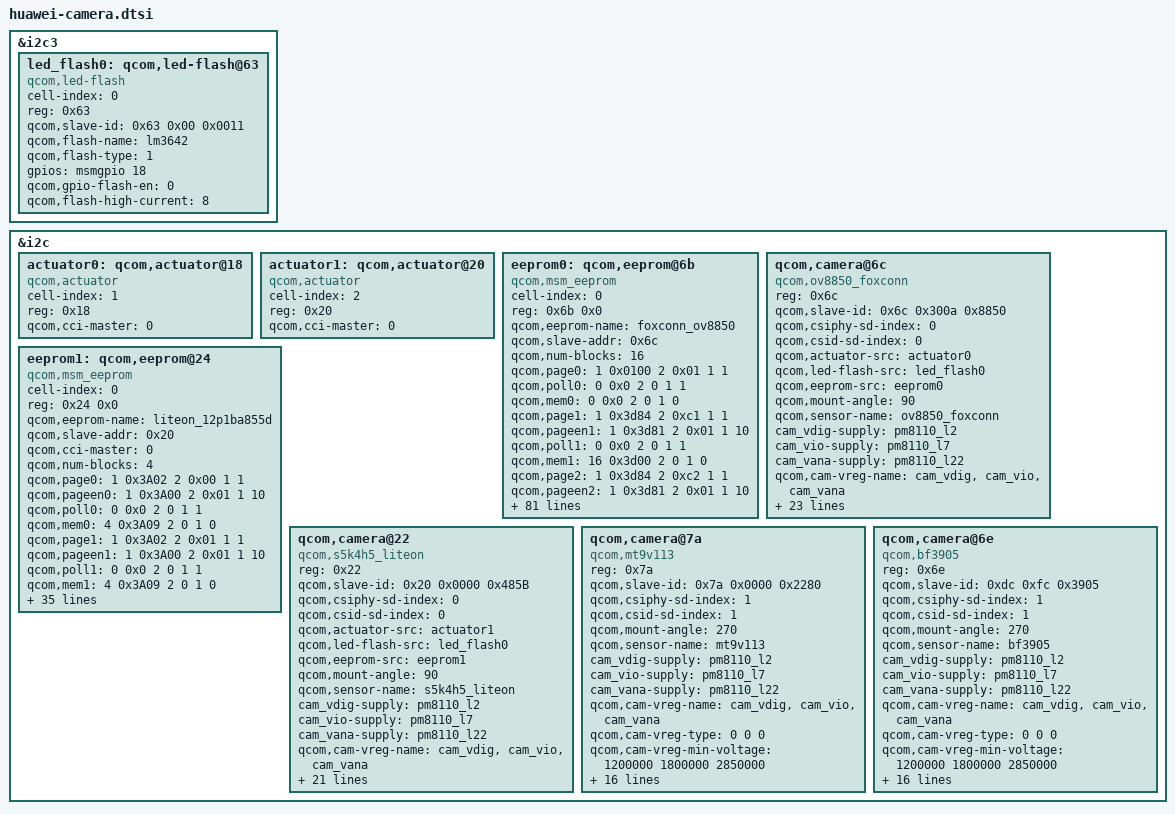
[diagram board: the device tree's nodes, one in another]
/*
 * Copyright (c) 2012-2013, The Linux Foundation. All rights reserved.
 *
 * This program is free software; you can redistribute it and/or modify
 * it under the terms of the GNU General Public License version 2 and
 * only version 2 as published by the Free Software Foundation.
 *
 * This program is distributed in the hope that it will be useful,
 * but WITHOUT ANY WARRANTY; without even the implied warranty of
 * MERCHANTABILITY or FITNESS FOR A PARTICULAR PURPOSE.  See the
 * GNU General Public License for more details.
 */
&i2c3 {
       led_flash0: qcom,led-flash@63 {
		cell-index = <0>;
		reg = <0x63>;
		qcom,slave-id = <0x63 0x00 0x0011>;
		compatible = "qcom,led-flash";
		qcom,flash-name = "lm3642";
		qcom,flash-type = <1>;
		gpios = <&msmgpio 18 0>;
		qcom,gpio-flash-en = <0>;
		// 8 corresponds to 656.25mA
		qcom,flash-high-current = <8>;
       };
};

&i2c {

		actuator0: qcom,actuator@18 {
			cell-index = <1>;
			reg = <0x18>;
			compatible = "qcom,actuator";
			qcom,cci-master = <0>;
		};
		actuator1: qcom,actuator@20 {
			cell-index = <2>;
			reg = <0x20>;
			compatible = "qcom,actuator";
			qcom,cci-master = <0>;
		};
		eeprom0: qcom,eeprom@6b {
		cell-index = <0>;
		reg = <0x6b 0x0>;
		qcom,eeprom-name = "foxconn_ov8850";
		compatible = "qcom,msm_eeprom";
		qcom,slave-addr = <0x6c>;
		qcom,num-blocks = <16>;

		qcom,page0 = <1 0x0100 2 0x01 1 1>;
		qcom,poll0 = <0 0x0 2 0 1 1>;
		qcom,mem0 = <0 0x0 2 0 1 0>;
		qcom,page1 = <1 0x3d84 2 0xc1 1 1>;
		qcom,pageen1 = <1 0x3d81 2 0x01 1 10>;
		qcom,poll1 = <0 0x0 2 0 1 1>;
		qcom,mem1 = <16 0x3d00 2 0 1 0>;
		qcom,page2 = <1 0x3d84 2 0xc2 1 1>;
		qcom,pageen2 = <1 0x3d81 2 0x01 1 10>;
		qcom,poll2 = <0 0x0 2 0 1 1>;
		qcom,mem2 = <16 0x3d00 2 0 1 0>;
		qcom,page3 = <1 0x3d84 2 0xc3 1 1>;
		qcom,pageen3 = <1 0x3d81 2 0x01 1 10>;
		qcom,poll3 = <0 0x0 2 0 1 1>;
		qcom,mem3 = <16 0x3d00 2 0 1 0>;
		qcom,page4 = <1 0x3d84 2 0xc4 1 1>;
		qcom,pageen4 = <1 0x3d81 2 0x01 1 10>;
		qcom,poll4 = <0 0x0 2 0 1 1>;
		qcom,mem4 = <16 0x3d00 2 0 1 0>;
		qcom,page5 = <1 0x3d84 2 0xc5 1 1>;
		qcom,pageen5 = <1 0x3d81 2 0x01 1 10>;
		qcom,poll5 = <0 0x0 2 0 1 1>;
		qcom,mem5 = <16 0x3d00 2 0 1 0>;
		qcom,page6 = <1 0x3d84 2 0xc6 1 1>;
		qcom,pageen6 = <1 0x3d81 2 0x01 1 10>;
		qcom,poll6 = <0 0x0 2 0 1 1>;
		qcom,mem6 = <16 0x3d00 2 0 1 0>;
		qcom,page7 = <1 0x3d84 2 0xc7 1 1>;
		qcom,pageen7 = <1 0x3d81 2 0x01 1 10>;
		qcom,poll7 = <0 0x0 2 0 1 1>;
		qcom,mem7 = <16 0x3d00 2 0 1 0>;
		qcom,page8 = <1 0x3d84 2 0xc8 1 1>;
		qcom,pageen8 = <1 0x3d81 2 0x01 1 10>;
		qcom,poll8 = <0 0x0 2 0 1 1>;
		qcom,mem8 = <16 0x3d00 2 0 1 0>;
		qcom,page9 = <1 0x3d84 2 0xc9 1 1>;
		qcom,pageen9 = <1 0x3d81 2 0x01 1 10>;
		qcom,poll9 = <0 0x0 2 0 1 1>;
		qcom,mem9 = <16 0x3d00 2 0 1 0>;
		qcom,page10 = <1 0x3d84 2 0xca 1 1>;
		qcom,pageen10 = <1 0x3d81 2 0x01 1 10>;
		qcom,poll10 = <0 0x0 2 0 1 1>;
		qcom,mem10 = <16 0x3d00 2 0 1 0>;
		qcom,page11 = <1 0x3d84 2 0xcb 1 1>;
		qcom,pageen11 = <1 0x3d81 2 0x01 1 10>;
		qcom,poll11 = <0 0x0 2 0 1 1>;
		qcom,mem11 = <16 0x3d00 2 0 1 0>;
		qcom,page12 = <1 0x3d84 2 0xcc 1 1>;
		qcom,pageen12 = <1 0x3d81 2 0x01 1 10>;
		qcom,poll12 = <0 0x0 2 0 1 1>;
		qcom,mem12 = <16 0x3d00 2 0 1 0>;
		qcom,page13 = <1 0x3d84 2 0xcd 1 1>;
		qcom,pageen13 = <1 0x3d81 2 0x01 1 10>;
		qcom,poll13 = <0 0x0 2 0 1 1>;
		qcom,mem13 = <16 0x3d00 2 0 1 0>;
		qcom,page14 = <1 0x3d84 2 0xce 1 1>;
		qcom,pageen14 = <1 0x3d81 2 0x01 1 10>;
		qcom,poll14 = <0 0x0 2 0 1 1>;
		qcom,mem14 = <16 0x3d00 2 0 1 0>;
		qcom,page15 = <1 0x3d84 2 0xcf 1 1>;
		qcom,pageen15 = <1 0x3d81 2 0x01 1 10>;
		qcom,poll15 = <0 0x0 2 0 1 1>;
		qcom,mem15 = <16 0x3d00 2 0 1 0>;

		cam_vdig-supply = <&pm8110_l2>;
		cam_vio-supply = <&pm8110_l7>;
		cam_vana-supply = <&pm8110_l22>;
		qcom,cam-vreg-name = "cam_vdig", "cam_vio", "cam_vana";
		qcom,cam-vreg-type = <0 0 0>;
		qcom,cam-vreg-min-voltage = <0 1800000 2850000>;
		qcom,cam-vreg-max-voltage = <0 1800000 2850000>;
		qcom,cam-vreg-op-mode = <0 200000 100000>;
		qcom,gpio-no-mux = <0>;
		gpios = <&msmgpio 13 0>,
			<&msmgpio 21 0>,//reset
			<&msmgpio 20 0>,//stanby
			<&msmgpio 101 0>; //dvdd_en
		qcom,gpio-reset = <1>;
		qcom,gpio-standby = <2>;
		qcom,gpio-vdig = <3>;
		qcom,gpio-req-tbl-num = <0 1 2 3>;
		qcom,gpio-req-tbl-flags = <1 0 0 0>;
		qcom,gpio-req-tbl-label = "CAMIF_MCLK",
			"CAM_RESET1",
			"CAM_STANDBY",
			"CAM_DVDD_EN";
		qcom,cam-power-seq-type = "sensor_gpio",
			"sensor_vreg", "sensor_vreg", "sensor_clk",
			"sensor_gpio", "sensor_gpio";
		qcom,cam-power-seq-val = "sensor_gpio_vdig",
			"cam_vio", "cam_vana", "sensor_cam_mclk",
			"sensor_gpio_reset",
			"sensor_gpio_standby";
		qcom,cam-power-seq-cfg-val = <1 1 1 24000000 1 1>;
		qcom,cam-power-seq-delay = <1 1 5 5 5 10>;
	};	
		/* change the mount angle of the ov8850 & s5k4h5 from 270 to 90*/
		qcom,camera@6c {
				compatible = "qcom,ov8850_foxconn";
				reg = <0x6c>;
				qcom,slave-id = <0x6c 0x300a 0x8850>;
				qcom,csiphy-sd-index = <0>;
				qcom,csid-sd-index = <0>;
				qcom,actuator-src = <&actuator0>;
				qcom,led-flash-src = <&led_flash0>;
				qcom,eeprom-src = <&eeprom0>;
				qcom,mount-angle = <90>;
				qcom,sensor-name = "ov8850_foxconn";
				cam_vdig-supply = <&pm8110_l2>;
				cam_vio-supply = <&pm8110_l7>;
				cam_vana-supply = <&pm8110_l22>;
				qcom,cam-vreg-name = "cam_vdig", "cam_vio", "cam_vana";
				qcom,cam-vreg-type = <0 0 0>;
				qcom,cam-vreg-min-voltage = <1200000 1800000 2850000>;
				qcom,cam-vreg-max-voltage = <1200000 1800000 2850000>;
				qcom,cam-vreg-op-mode = <200000 200000 100000>;
				qcom,gpio-no-mux = <0>;
				gpios = <&msmgpio 13 0>,
					<&msmgpio 21 0>,//reset
					<&msmgpio 20 0>,//stanby
					<&msmgpio 101 0>, //dvdd_en
					<&msmgpio 79 0>; //vcm_pwdn
				qcom,gpio-reset = <1>;
				qcom,gpio-standby = <2>;
				qcom,gpio-vdig = <3>;
				qcom,gpio-af-pwdm = <4>;
				qcom,gpio-req-tbl-num = <0 1 2 3 4>;
				qcom,gpio-req-tbl-flags = <1 0 0 0 0>;
				qcom,gpio-req-tbl-label = "CAMIF_MCLK",
					"CAM_RESET1",
					"CAM_STANDBY",
					"CAM_DVDDEN",
					"CAM_VCMPWDN";
				qcom,csi-lane-assign = <0xe4>;
				qcom,csi-lane-mask = <0x7>;
				qcom,sensor-position = <0>;
				qcom,sensor-mode = <1>;
				qcom,cci-master = <0>;
			};
		eeprom1: qcom,eeprom@24 {		
				cell-index = <0>;		
				reg = <0x24 0x0>;		
				qcom,eeprom-name = "liteon_12p1ba855d";	
				compatible = "qcom,msm_eeprom";		
				qcom,slave-addr = <0x20>;	
				qcom,cci-master = <0>;
				qcom,num-blocks = <4>;	
				qcom,page0 = <1 0x3A02 2 0x00 1 1>;	
				qcom,pageen0 = <1 0x3A00 2 0x01 1 10>;	
				qcom,poll0 = <0 0x0 2 0 1 1>;	
				qcom,mem0 = <4 0x3A09 2 0 1 0>;	
				qcom,page1 = <1 0x3A02 2 0x01 1 1>;	
				qcom,pageen1 = <1 0x3A00 2 0x01 1 10>;	
				qcom,poll1 = <0 0x0 2 0 1 1>;	
				qcom,mem1 = <4 0x3A09 2 0 1 0>;	
				qcom,page2 = <1 0x3A02 2 0x02 1 1>;	
				qcom,pageen2 = <1 0x3A00 2 0x01 1 10>;	
				qcom,poll2 = <0 0x0 2 0 1 1>;	
				qcom,mem2 = <4 0x3A09 2 0 1 0>;	
				qcom,page3 = <1 0x3A02 2 0x03 1 1>;	
				qcom,pageen3 = <1 0x3A00 2 0x01 1 10>;	
				qcom,poll3 = <0 0x0 2 0 1 1>;	
				qcom,mem3 = <4 0x3A09 2 0 1 0>;	
				
				cam_vdig-supply = <&pm8110_l2>;	
				cam_vio-supply = <&pm8110_l7>;	
				cam_vana-supply = <&pm8110_l22>;
				qcom,cam-vreg-name = "cam_vdig", "cam_vio", "cam_vana";
				qcom,cam-vreg-type = <0 0 0>;
				qcom,cam-vreg-min-voltage = <1200000 1800000 2850000>;
				qcom,cam-vreg-max-voltage = <1200000 1800000 2850000>;
				qcom,cam-vreg-op-mode = <200000 200000 100000>;
				
				qcom,gpio-no-mux = <0>;
				gpios = <&msmgpio 13 0>,		
					<&msmgpio 21 0>,//reset
					<&msmgpio 101 0>; //dvdd_en
				qcom,gpio-reset = <1>;	
				qcom,gpio-vdig  = <2>;
				qcom,gpio-req-tbl-num = <0 1 2>;
				qcom,gpio-req-tbl-flags = <1 0 0>;	
				qcom,gpio-req-tbl-label = "CAMIF_MCLK",	
					"CAM_RESET1",
					"CAM_DVDD_EN";
				qcom,cam-power-seq-type = "sensor_gpio",
					"sensor_vreg", 
					"sensor_vreg",
					"sensor_vreg",
					"sensor_clk",		
					"sensor_gpio";		
				qcom,cam-power-seq-val = "sensor_gpio_vdig",
					"cam_vdig",
					"cam_vana",
					"cam_vio", 
					"sensor_cam_mclk",			
					"sensor_gpio_reset";	
				qcom,cam-power-seq-cfg-val = <1 1 1 1 24000000 1>;	
				qcom,cam-power-seq-delay =   <1 1 1 1 5 5>;
		};
		qcom,camera@22 {
				compatible = "qcom,s5k4h5_liteon";
				reg = <0x22>;
				qcom,slave-id = <0x20 0x0000 0x485B>;
				qcom,csiphy-sd-index = <0>;
				qcom,csid-sd-index = <0>;
				qcom,actuator-src = <&actuator1>;
				qcom,led-flash-src = <&led_flash0>;
				qcom,eeprom-src = <&eeprom1>;
				qcom,mount-angle = <90>;
				qcom,sensor-name = "s5k4h5_liteon";
				cam_vdig-supply = <&pm8110_l2>;
				cam_vio-supply = <&pm8110_l7>;
				cam_vana-supply = <&pm8110_l22>;
				qcom,cam-vreg-name = "cam_vdig", "cam_vio", "cam_vana";
				qcom,cam-vreg-type = <0 0 0>;
				qcom,cam-vreg-min-voltage = <1200000 1800000 2850000>;
				qcom,cam-vreg-max-voltage = <1200000 1800000 2850000>;
				qcom,cam-vreg-op-mode = <200000 200000 100000>;
				qcom,gpio-no-mux = <0>;
				gpios = <&msmgpio 13 0>,
					<&msmgpio 21 0>,//reset
					<&msmgpio 101 0>, //dvdd_en
					<&msmgpio 79 0>; //vcm_pwdn
				qcom,gpio-reset = <1>;
				qcom,gpio-vdig = <2>;
				qcom,gpio-af-pwdm = <3>;
				qcom,gpio-req-tbl-num = <0 1 2 3>;
				qcom,gpio-req-tbl-flags = <1 0 0 0>;
				qcom,gpio-req-tbl-label = "CAMIF_MCLK",
					"CAM_RESET1",
					"CAM_DVDDEN",
					"CAM_VCMPWDN";
				qcom,csi-lane-assign = <0xe4>;
				qcom,csi-lane-mask = <0x3>;
				qcom,sensor-position = <0>;
				qcom,sensor-mode = <1>;
				qcom,cci-master = <0>;
			};
			
  qcom,camera@7a {
		  compatible = "qcom,mt9v113";
		  reg = <0x7a>;
		  qcom,slave-id = <0x7a 0x0000 0x2280>;
		  qcom,csiphy-sd-index = <1>;
		  qcom,csid-sd-index = <1>;
		  qcom,mount-angle = <270>;
		  qcom,sensor-name = "mt9v113";
		  cam_vdig-supply = <&pm8110_l2>;
		  cam_vio-supply = <&pm8110_l7>;
		  cam_vana-supply = <&pm8110_l22>;
		  qcom,cam-vreg-name = "cam_vdig", "cam_vio", "cam_vana";
		  qcom,cam-vreg-type = <0 0 0>;
		  qcom,cam-vreg-min-voltage = <1200000 1800000 2850000>;
		  qcom,cam-vreg-max-voltage = <1200000 1800000 2850000>;
		  qcom,cam-vreg-op-mode = <200000 200000 100000>;
		  qcom,gpio-no-mux = <0>;
		  gpios = <&msmgpio 13 0>,
		  	<&msmgpio 15 0>,
		  	<&msmgpio 85 0>;
		  qcom,gpio-reset = <1>;
		  qcom,gpio-standby = <2>;
		  qcom,gpio-req-tbl-num = <0 1 2>;
		  qcom,gpio-req-tbl-flags = <1 0 0>;
		  qcom,gpio-req-tbl-label = "CAMIF_MCLK",
		  			  "CAM_RESET",
		  			  "CAM_STANDBY";
		  qcom,csi-lane-assign = <0xe4>;
		  qcom,csi-lane-mask = <0x3>;
		  qcom,sensor-position = <1>;
		  qcom,sensor-mode = <1>;
		  qcom,cci-master = <0>;
	};

	qcom,camera@6e {
		compatible = "qcom,bf3905";
		reg = <0x6e>;
		qcom,slave-id = <0xdc 0xfc 0x3905>;
		qcom,csiphy-sd-index = <1>;
		qcom,csid-sd-index = <1>;
		qcom,mount-angle = <270>;
		qcom,sensor-name = "bf3905";
		cam_vdig-supply = <&pm8110_l2>;
		cam_vio-supply = <&pm8110_l7>;
		cam_vana-supply = <&pm8110_l22>;
		qcom,cam-vreg-name = "cam_vdig", "cam_vio", "cam_vana";
		qcom,cam-vreg-type = <0 0 0>;
		qcom,cam-vreg-min-voltage = <1200000 1800000 2850000>;
		qcom,cam-vreg-max-voltage = <1200000 1800000 2850000>;
		qcom,cam-vreg-op-mode = <200000 200000 100000>;
		qcom,gpio-no-mux = <0>;
		gpios = <&msmgpio 13 0>,
			<&msmgpio 15 0>,
			<&msmgpio 85 0>;
		qcom,gpio-reset = <1>;
		qcom,gpio-standby = <2>;
		qcom,gpio-req-tbl-num = <0 1 2>;
		qcom,gpio-req-tbl-flags = <1 0 0>;
		qcom,gpio-req-tbl-label = "CAMIF_MCLK",
					  "CAM_RESET",
					  "CAM_STANDBY";
		qcom,csi-lane-assign = <0xe4>;
		qcom,csi-lane-mask = <0x3>;
		qcom,sensor-position = <1>;
		qcom,sensor-mode = <1>;
		qcom,cci-master = <0>;
	};
};
